# SPINLOCK register map
Vendor: Texas Instruments
Peripheral module from a debugger description file (folder am437x).
Registers are 32-bit, access per field, no defined reset value unless marked. A register's access mark holds for its fields unless they carry their own. Offsets are as the file gives them; lines under a group give offsets from that group; [hi:lo] are bit positions; {n}, {i} and the like mark numbered series; 'fields as' and 'values as' point back to an identical list; <NAME> marks a mode.

## SPINLOCK
0x00 SPINLOCK_REV ro — Read-only IP revision identifier (X.Y.R) used by software to determine features, bugs and compatibility of an instance of this the Spin Lock module.
  [31:0] REV — IP Revision Code.
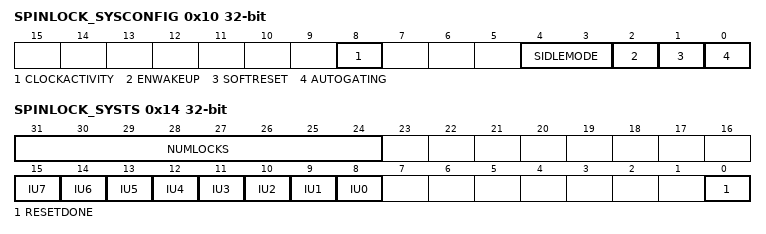
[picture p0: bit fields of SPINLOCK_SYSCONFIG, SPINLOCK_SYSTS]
0x10 SPINLOCK_SYSCONFIG — This register controls the various parameters of the OCP interface. Note that several fields are present by read-only.
  [8] CLOCKACTIVITY ro — Indicates whether the module requires the OCP when in IDLE mode.
    1=en_2_0x1 (OCP clock is required by the module, even during idle mode.); 0=en_1_0x0 (OCP clock is not required by the module during IDLE mode and may be switched off.)
  [4:3] SIDLEMODE ro — Control of the slave interface power management IDLE request acknowledgement.
    3=en_4_0x3 (Reserved. Do not use.); 2=en_3_0x2 (IDLE request acknowledgement is based on the internal module activity.); 1=en_2_0x1 (IDLE request is never acknowledged.); 0=en_1_0x0 (IDLE request is acknowledged unconditionally and immediately.)
  [2] ENWAKEUP ro — Asynchronous wakeup gereration.
    1=en_2_0x1 (Enable wakeup generation.); 0=en_1_0x0 (Wakeup generation is disabled.)
  [1] SOFTRESET wo — Module software reset.
    1=en_2_0x1 (Start a soft reset sequence of the Spin Lock module.); 0=en_1_0x0
  [0] AUTOGATING ro — Internal OCP clock gating strategy.
    1=en_2_0x1 (Automatic internal OCP clock gating strategy is applied, based on the OCP interface activity.); 0=en_1_0x0 (OCP clock is not gated when OCP interface is idle.)
0x14 SPINLOCK_SYSTS ro — This register provides status information about this instance of the Spin Lock module.
  [31:24] NUMLOCKS
  [n+8] IU{n} (n=2..7)
  [9] IU1 — In-Use flag 1, covering lock registers [[br]]32 - 63. [[br]]Reads as one only if one or more lock registers in this range are TAKEN. [[br]]If no lock registers are implemented in this range, then this flag always reads as 0.
  [8] IU0 — In-Use flag 0, covering lock registers [[br]]0 - 31. [[br]]Reads as one only if one or more lock registers in this range are TAKEN.
  [0] RESETDONE — [[br]]0: Reset in progress. [[br]]1: Reset is completed.
{0x800+4i} SPINLOCK_REG_{i} (i=0..31) — This register is read when attempting to acquire a lock. The lock is automatically taken if it was not taken and the value returned by the read is zero. If the lock was already taken, then the read returns one. Writing a zero to this register frees the lock.
  [0] TAKEN rw
